# TC37XPD register map
Vendor: Infineon; Series: ATVMC; File version: 100
CPU: other r0p0, little endian, MPU, FPU, vendor SysTick, 4 interrupt priority bits
Registers are 32-bit, read-write, reset 0x0 unless marked. A register's access mark holds for its fields unless they carry their own. Offsets are from the block's base; [hi:lo] are bit positions; lines under a group give offsets from that group; {n}, {i} and the like mark numbered series.

## FCE
Base 0xF0000000
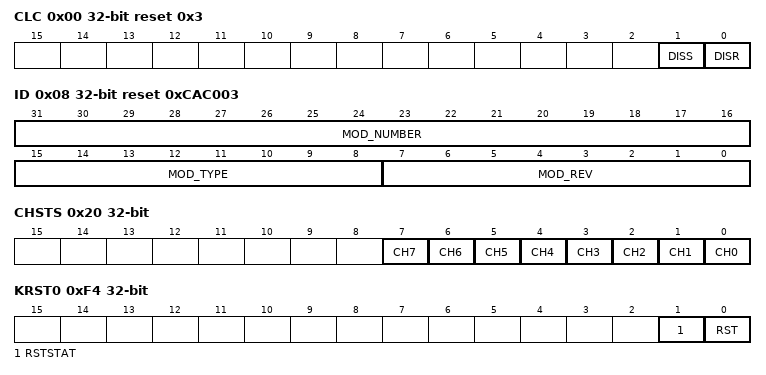
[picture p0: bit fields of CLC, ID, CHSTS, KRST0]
0x00 CLC access per field reset 0x3 — Clock Control Register resetvalue={Application Reset:0x3}
  [1] DISS ro — Module Disable Status Bit DISS. Bit indicates the current status of the module.
  [0] DISR rw — Module Disable Request Bit DISR. Used for enable disable control of the module.
0x08 ID ro reset 0xCAC003 — Module Identification Register resetvalue={Application Reset:0x0CAC003}
  [31:16] MOD_NUMBER — Module Number Value MOD NUMBER. This bit field defines a module identification number. The value for the FCE module is 00CA H .
  [15:8] MOD_TYPE — Module Type MOD TYPE. The bit field is set to C0H which defines the module as a 32 bit module.
  [7:0] MOD_REV — Module Revision Number MOD REV. This bit field defines the module revision number. The value of a module revision starts with 01H first revision . The current revision number is 03H.
0x20 CHSTS ro — Channels Status Register resetvalue={Application Reset:0x0}
  [n] CH{n} (n=0..7) — Channel{n} Status CH{n}. This bit is the result of an OR operation of the various status bits of channel {n} see STS register .
0xEC KRSTCLR wo — Kernel Reset Status Clear Register resetvalue={Application Reset:0x0}
  [0] CLR — Kernel Reset Status Clear CLR. Read always as 0.
0xF0 KRST1 — Kernel Reset Register 1 resetvalue={Application Reset:0x0}
  [0] RST — Kernel Reset RST. This reset bit can be used to request for a kernel reset. The kernel reset will be executed if the reset bits of both kernel reset registers is set. The RST bit will be cleared re set to 0 by the BPI FPI after the kernel reset was executed.
0xF4 KRST0 access per field — Kernel Reset Register 0 resetvalue={Application Reset:0x0}
  [1] RSTSTAT ro — Kernel Reset Status RSTSTAT. This bit indicates wether a kernel reset was executed or not. This bit is set by the BPI FPI after the execution of a kernel reset in the same clock cycle both reset bits. This bit can be cleared by writing with 1 to the CLR bit in the related KRSTCLR register.
  [0] RST rw — Kernel Reset RST. This reset bit can be used to request for a kernel reset. The kernel reset will be executed if the reset bits of both kernel registers are set. The RST bit will be cleared re set to 0 by the BPI FPI after the kernel reset was executed.
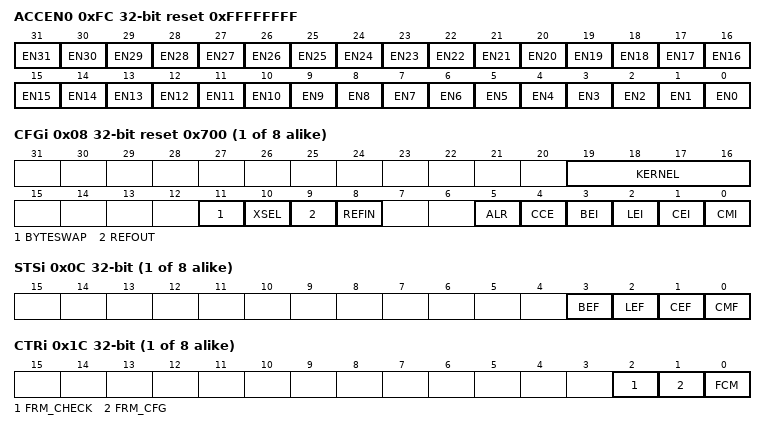
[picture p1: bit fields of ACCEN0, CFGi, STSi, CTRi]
0xFC ACCEN0 reset 0xFFFFFFFF — Access Enable Register 0 resetvalue={Application Reset:0x0FFFFFFFF}
  [n] EN{n} (n=0..31) — Access Enable for Master TAG ID 31 EN31. This bit enables write access to the module kernel addresses for transactions with the Master TAG ID n
{0x100+0x20*i} IN[{i}] (i=0..7) group
  0x00 IRi — Input Register 0 resetvalue={Application Reset:0x0}
    [31:0] IR — Input Register IR. This bit field holds the input data to be computed. In case the channel is configured to use 16 bit or 8 bit CRC only the LSB 16 or 8 bits will be used as input.
  0x04 RESi ro reset 0xFFFFFFFF — CRC Result Register 0 resetvalue={Application Reset:0x0FFFFFFFF}
    [31:0] RES — Result Register RES. Returns the final CRC value including CRC reflection and final XOR according to the CFG register configuration. Writing to this register produces a bus error. If the channel is configured to use 16 bit or 8 bit CRC the MSB 16 or 24 bits respectively shall be read as 0.
  0x08 CFGi reset 0x700 — CRC Configuration Register 0 resetvalue={Application Reset:0x700}
    [19:16] KERNEL — Selects the CRC Kernel Polynomial Engine used by this channel. KERNEL. Other possible values are reserved for additional kernels that may be added in the future. If these values are used then KERNEL3 is used by default.
    [11] BYTESWAP — Swaps the order of the bytes in the IR input register. BYTESWAP
    [10] XSEL — Selects the value to be xored with the final CRC XSEL
    [9] REFOUT — CRC Bit Wise Reflection REFOUT. The alignment of the reflection is the same as the kernel polynomial width. Eg. 32 bit kernel Bitwise reflection by 32 bits.
    [8] REFIN — IR Byte Wise Reflection REFIN
    [5] ALR — Automatic Length Reload ALR
    [4] CCE — CRC Check Comparison CCE
    [3] BEI — Bus Error Interrupt BEI. When enabled an interrupt BEF is generated if a bus write transaction with an access width smaller than the kernel width is issued to the input register. In this case the corresponding value written to the IR is discarded and no CRC computation takes place.
    [2] LEI — Length Error Interrupt LEI. When enabled a Length Error Interrupt is generated if software writes to IR register with LENGTH equal to 0 and CFG.CCE is set to 1.
    [1] CEI — Configuration Error Interrupt CEI. When enabled a Configuration Error Interrupt is generated whenever a mismatch is detected in the CFG and CHECK redundant registers.
    [0] CMI — CRC Mismatch Interrupt CMI
  0x0C STSi — CRC Status Register 0 resetvalue={Application Reset:0x0}
    [3] BEF — Bus Error Flag BEF. This bit is set per hardware only. To clear this bit software must write a 0 to this bit field location. Writing 1 has no effect.
    [2] LEF — Length Error Flag LEF. This bit is set per hardware only. To clear this bit software must write a 0 to this bit field location. Writing 1 has no effect.
    [1] CEF — Configuration Error Flag CEF. This bit is set per hardware only. To clear this bit software must write a 0 to this bit field location. Writing a 1 has no effect.
    [0] CMF — CRC Mismatch Flag CMF. This bit is set per hardware only. To clear this bit software must write a 0 to this bit field location. Writing 1 to this bit has no effect.
  0x10 LENGTHi — CRC Length Register 0 resetvalue={Application Reset:0x0}
    [15:0] LENGTH — Message Length Register LENGTH. Number of words bit width of each word in terms of KERNEL polynomial width building the message over which the CRC checksum is calculated. This bit field is modified by the hardware every write to the IR register decrements the value of the LENGTH bit field. If the CFG.ALR field is set to 1 the LENGTH field shall be reloaded with its configuration value at the end of the cycle where LENGTH reaches 0.
  0x14 CHECKi — CRC Check Register 0 resetvalue={Application Reset:0x0}
    [31:0] CHECK — CHECK Register CHECK. Expected CRC value to be checked by the hardware upon detection of a 1 to 0 transition of the LENGTH register. The comparison is enabled by the CFG.CCE bit field
  0x18 CRCi — CRC Regsister 0 resetvalue={Application Reset:0x0}
    [31:0] CRC — CRC Register CRC. This register enables to directly access the internal CRC register
  0x1C CTRi — CRC Test Register 0 resetvalue={Application Reset:0x0}
    [2] FRM_CHECK — Force Check Register Mismatch FRM CHECK. This field is used to control the error injection mechanism used to check the compare logic of the redundant CHECK registers. This is a one shot operation. The hardware detects a 0 to 1 transition of this bit field and triggers a Check Register Mismatch interrupt if enabled by the corresponding CFGm register .
    [1] FRM_CFG — Force CFG Register Mismatch FRM CFG. This field is used to control the error injection mechanism used to check the compare logic of the redundant CFG registers. This is a one shot operation. When the hardware detects a 0 to 1 transition of this bit field it triggers a Configuration Mismatch interrupt if enabled by the corresponding CFGm register .
    [0] FCM — Force CRC Mismatch FCM. Forces the CRC compare logic to issue an error regardless of the CHECK and CRC values. The hardware detects a 0 to 1 transition of this bit field and triggers a CRC Mismatch interrupt
